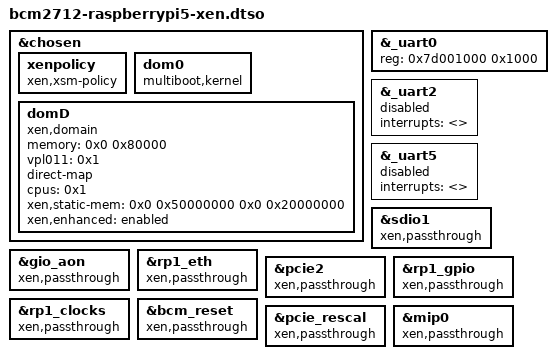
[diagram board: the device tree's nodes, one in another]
/*
 * Copyright (c) 2024 EPAM systems
 *
 * SPDX-License-Identifier: Apache-2.0
*/
/dts-v1/;
/plugin/;

&chosen {
	#address-cells = <0x2>;
	#size-cells = <0x2>;
	xenpolicy {
		compatible = "xen,xsm-policy", "multiboot-module";
	};
	dom0 {
		compatible = "multiboot,kernel", "multiboot,module";
	};
	domD {
		compatible = "xen,domain";
		#address-cells = <0x2>;
		#size-cells = <0x2>;
		memory = <0x0 0x80000>;
		vpl011 = <0x1>;
		direct-map;
		cpus = <0x1>;
		xen,static-mem = <0x0 0x50000000 0x0 0x20000000>;
		xen,enhanced = "enabled";
	};
};

/*
 * HACK uart regs to be xen page aligned to avoid XEN fail in dom0less mode
 * when vuart "vpl011" is used for DomU
 */
&_uart0 {
	reg = <0x7d001000 0x1000>;
};

/*
 * HACK there is number of uarts use same IRQ, so XEN fails when uses
 * _uart0 as console uart.
 * Delete interrupts info and disable devices;
 */
&_uart2 {
	interrupts = <>;
	status = "disabled";
};
&_uart5 {
	interrupts = <>;
	status = "disabled";
};

&sdio1          { xen,passthrough; };
&gio_aon        { xen,passthrough; };
&rp1_eth        { xen,passthrough; };
&pcie2          { xen,passthrough; };
&rp1_gpio       { xen,passthrough; };
&rp1_clocks     { xen,passthrough; };
&bcm_reset      { xen,passthrough; };
&pcie_rescal    { xen,passthrough; };
&mip0           { xen,passthrough; };
